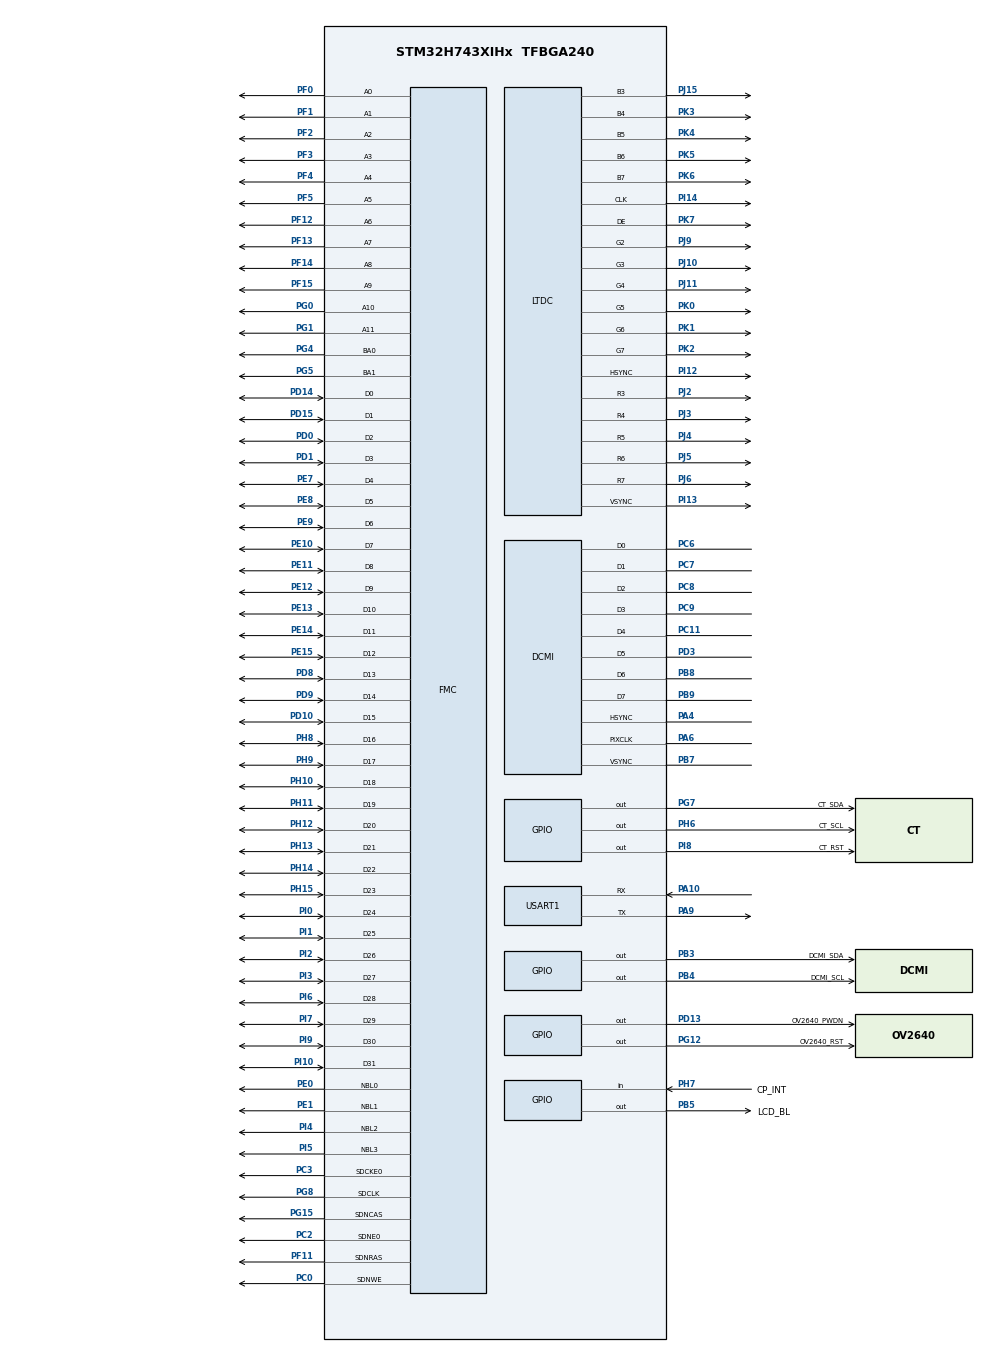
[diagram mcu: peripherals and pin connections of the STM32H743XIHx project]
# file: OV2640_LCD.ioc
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CORTEX_M7.AccessPermission_S-Cortex_Memory_Protection_Unit_Region1_Settings_S=MPU_REGION_FULL_ACCESS
CORTEX_M7.AccessPermission_S-Cortex_Memory_Protection_Unit_Region2_Settings_S=MPU_REGION_FULL_ACCESS
CORTEX_M7.AccessPermission_S-Cortex_Memory_Protection_Unit_Region3_Settings_S=MPU_REGION_FULL_ACCESS
CORTEX_M7.AccessPermission_S-Cortex_Memory_Protection_Unit_Region4_Settings_S=MPU_REGION_FULL_ACCESS
CORTEX_M7.AccessPermission_S-Cortex_Memory_Protection_Unit_Region5_Settings_S=MPU_REGION_FULL_ACCESS
CORTEX_M7.AccessPermission_Spec=MPU_REGION_FULL_ACCESS
CORTEX_M7.BaseAddress_S-Cortex_Memory_Protection_Unit_Region1_Settings_S=0x24000000
CORTEX_M7.BaseAddress_S-Cortex_Memory_Protection_Unit_Region2_Settings_S=0x30000000
CORTEX_M7.BaseAddress_S-Cortex_Memory_Protection_Unit_Region3_Settings_S=0x38000000
CORTEX_M7.BaseAddress_S-Cortex_Memory_Protection_Unit_Region4_Settings_S=0x80000000
CORTEX_M7.BaseAddress_S-Cortex_Memory_Protection_Unit_Region5_Settings_S=0xC0000000
CORTEX_M7.BaseAddress_Spec=0x20000000
CORTEX_M7.CPU_DCache=Enabled
CORTEX_M7.CPU_ICache=Enabled
CORTEX_M7.DisableExec_S-Cortex_Memory_Protection_Unit_Region4_Settings_S=MPU_INSTRUCTION_ACCESS_DISABLE
CORTEX_M7.DisableExec_Spec=MPU_INSTRUCTION_ACCESS_ENABLE
CORTEX_M7.Enable_S-Cortex_Memory_Protection_Unit_Region1_Settings_S=MPU_REGION_ENABLE
CORTEX_M7.Enable_S-Cortex_Memory_Protection_Unit_Region2_Settings_S=MPU_REGION_ENABLE
CORTEX_M7.Enable_S-Cortex_Memory_Protection_Unit_Region3_Settings_S=MPU_REGION_ENABLE
CORTEX_M7.Enable_S-Cortex_Memory_Protection_Unit_Region4_Settings_S=MPU_REGION_ENABLE
CORTEX_M7.Enable_S-Cortex_Memory_Protection_Unit_Region5_Settings_S=MPU_REGION_ENABLE
CORTEX_M7.IsBufferable_S-Cortex_Memory_Protection_Unit_Region1_Settings_S=MPU_ACCESS_BUFFERABLE
CORTEX_M7.IsBufferable_S-Cortex_Memory_Protection_Unit_Region2_Settings_S=MPU_ACCESS_BUFFERABLE
CORTEX_M7.IsBufferable_S-Cortex_Memory_Protection_Unit_Region3_Settings_S=MPU_ACCESS_BUFFERABLE
CORTEX_M7.IsBufferable_S-Cortex_Memory_Protection_Unit_Region5_Settings_S=MPU_ACCESS_BUFFERABLE
CORTEX_M7.IsBufferable_Spec=MPU_ACCESS_BUFFERABLE
CORTEX_M7.IsCacheable_S-Cortex_Memory_Protection_Unit_Region1_Settings_S=MPU_ACCESS_CACHEABLE
CORTEX_M7.IsCacheable_S-Cortex_Memory_Protection_Unit_Region2_Settings_S=MPU_ACCESS_CACHEABLE
CORTEX_M7.IsCacheable_S-Cortex_Memory_Protection_Unit_Region3_Settings_S=MPU_ACCESS_CACHEABLE
CORTEX_M7.IsCacheable_S-Cortex_Memory_Protection_Unit_Region5_Settings_S=MPU_ACCESS_CACHEABLE
CORTEX_M7.IsCacheable_Spec=MPU_ACCESS_CACHEABLE
CORTEX_M7.IsShareable_Spec=MPU_ACCESS_NOT_SHAREABLE
CORTEX_M7.Size_S-Cortex_Memory_Protection_Unit_Region1_Settings_S=MPU_REGION_SIZE_512KB
CORTEX_M7.Size_S-Cortex_Memory_Protection_Unit_Region2_Settings_S=MPU_REGION_SIZE_512KB
CORTEX_M7.Size_S-Cortex_Memory_Protection_Unit_Region3_Settings_S=MPU_REGION_SIZE_64KB
CORTEX_M7.Size_S-Cortex_Memory_Protection_Unit_Region4_Settings_S=MPU_REGION_SIZE_256MB
CORTEX_M7.Size_S-Cortex_Memory_Protection_Unit_Region5_Settings_S=MPU_REGION_SIZE_64MB
CORTEX_M7.Size_Spec=MPU_REGION_SIZE_128KB
CORTEX_M7.SubRegionDisable_Spec=0x00
CORTEX_M7.default_mode_Activation=1
DCMI.PCKPolarity=DCMI_PCKPOLARITY_RISING
DMA2D.ColorMode=DMA2D_OUTPUT_RGB565
Dma.DCMI.1.Direction=DMA_PERIPH_TO_MEMORY
Dma.DCMI.1.EventEnable=DISABLE
Dma.DCMI.1.FIFOMode=DMA_FIFOMODE_ENABLE
Dma.DCMI.1.FIFOThreshold=DMA_FIFO_THRESHOLD_HALFFULL
Dma.DCMI.1.Instance=DMA1_Stream1
Dma.DCMI.1.MemBurst=DMA_MBURST_SINGLE
Dma.DCMI.1.MemDataAlignment=DMA_MDATAALIGN_WORD
Dma.DCMI.1.MemInc=DMA_MINC_ENABLE
Dma.DCMI.1.Mode=DMA_CIRCULAR
Dma.DCMI.1.PeriphBurst=DMA_PBURST_SINGLE
Dma.DCMI.1.PeriphDataAlignment=DMA_PDATAALIGN_WORD
Dma.DCMI.1.PeriphInc=DMA_PINC_DISABLE
Dma.DCMI.1.Polarity=HAL_DMAMUX_REQ_GEN_RISING
Dma.DCMI.1.Priority=DMA_PRIORITY_HIGH
Dma.DCMI.1.RequestNumber=1
Dma.DCMI.1.SignalID=NONE
Dma.DCMI.1.SyncEnable=DISABLE
Dma.DCMI.1.SyncPolarity=HAL_DMAMUX_SYNC_NO_EVENT
Dma.DCMI.1.SyncRequestNumber=1
Dma.DCMI.1.SyncSignalID=NONE
Dma.Request0=USART1_RX
Dma.Request1=DCMI
Dma.USART1_RX.0.Direction=DMA_PERIPH_TO_MEMORY
Dma.USART1_RX.0.EventEnable=DISABLE
Dma.USART1_RX.0.FIFOMode=DMA_FIFOMODE_DISABLE
Dma.USART1_RX.0.Instance=DMA1_Stream0
Dma.USART1_RX.0.MemDataAlignment=DMA_MDATAALIGN_BYTE
Dma.USART1_RX.0.MemInc=DMA_MINC_ENABLE
Dma.USART1_RX.0.Mode=DMA_NORMAL
Dma.USART1_RX.0.PeriphDataAlignment=DMA_PDATAALIGN_BYTE
Dma.USART1_RX.0.PeriphInc=DMA_PINC_DISABLE
Dma.USART1_RX.0.Polarity=HAL_DMAMUX_REQ_GEN_RISING
Dma.USART1_RX.0.Priority=DMA_PRIORITY_LOW
Dma.USART1_RX.0.RequestNumber=1
Dma.USART1_RX.0.SignalID=NONE
Dma.USART1_RX.0.SyncEnable=DISABLE
Dma.USART1_RX.0.SyncPolarity=HAL_DMAMUX_SYNC_NO_EVENT
Dma.USART1_RX.0.SyncRequestNumber=1
Dma.USART1_RX.0.SyncSignalID=NONE
FMC.CASLatency1=FMC_SDRAM_CAS_LATENCY_2
FMC.ColumnBitsNumber1=FMC_SDRAM_COLUMN_BITS_NUM_9
FMC.ExitSelfRefreshDelay1=8
FMC.LoadToActiveDelay1=2
FMC.RCDDelay1=2
FMC.RPDelay1=2
FMC.RPDelay2=2
FMC.ReadBurst1=FMC_SDRAM_RBURST_ENABLE
FMC.ReadBurst2=FMC_SDRAM_RBURST_ENABLE
FMC.RowCycleDelay1=8
FMC.RowCycleDelay2=8
FMC.SDClockPeriod1=FMC_SDRAM_CLOCK_PERIOD_2
FMC.SDClockPeriod2=FMC_SDRAM_CLOCK_PERIOD_2
FMC.SelfRefreshTime1=5
FMC.WriteRecoveryTime1=4
LTDC.ActiveH=272
LTDC.ActiveW=480
LTDC.Alpha_L0=255
LTDC.BlendingFactor1_L0=LTDC_BLENDING_FACTOR1_PAxCA
LTDC.BlendingFactor2_L0=LTDC_BLENDING_FACTOR2_PAxCA
LTDC.FBStartAdress_L0=0xC0000000
LTDC.HBP=40
LTDC.HFP=5
LTDC.HSync=1
LTDC.ImageWidth_L0=480
LTDC.Layers=0
LTDC.PixelFormat_L0=LTDC_PIXEL_FORMAT_RGB565
LTDC.VBP=8
LTDC.VFP=3
LTDC.VSync=1
LTDC.WindowX1_L0=480
LTDC.WindowY1_L0=272
Mcu.Family=STM32H7
Mcu.Name=STM32H743XIHx
Mcu.Package=TFBGA240
NVIC.DCMI_IRQn=true\:0\:0\:false\:false\:true\:true\:true\:true
NVIC.DMA1_Stream0_IRQn=true\:0\:0\:false\:false\:true\:false\:true\:true
NVIC.DMA1_Stream1_IRQn=true\:0\:0\:false\:false\:true\:false\:true\:true
NVIC.PriorityGroup=NVIC_PRIORITYGROUP_4
NVIC.USART1_IRQn=true\:0\:0\:false\:false\:true\:true\:true\:true
PA10.Mode=Asynchronous
PA10.Signal=USART1_RX
PA13\ (JTMS/SWDIO).Mode=Serial_Wire
PA13\ (JTMS/SWDIO).Signal=DEBUG_JTMS-SWDIO
PA14\ (JTCK/SWCLK).Mode=Serial_Wire
PA14\ (JTCK/SWCLK).Signal=DEBUG_JTCK-SWCLK
PA4.GPIO_Speed=GPIO_SPEED_FREQ_VERY_HIGH
PA4.Mode=Slave_8_bits_External_Synchro
PA4.Signal=DCMI_HSYNC
PA6.GPIO_Speed=GPIO_SPEED_FREQ_VERY_HIGH
PA6.Mode=Slave_8_bits_External_Synchro
PA6.Signal=DCMI_PIXCLK
PA9.Mode=Asynchronous
PA9.Signal=USART1_TX
PB3\ (JTDO/TRACESWO).GPIO_Label=DCMI_SDA
PB3\ (JTDO/TRACESWO).GPIO_ModeDefaultOutputPP=GPIO_MODE_OUTPUT_OD
PB3\ (JTDO/TRACESWO).GPIO_PuPd=GPIO_PULLUP
PB3\ (JTDO/TRACESWO).GPIO_Speed=GPIO_SPEED_FREQ_VERY_HIGH
PB3\ (JTDO/TRACESWO).PinState=GPIO_PIN_SET
PB3\ (JTDO/TRACESWO).Signal=GPIO_Output
PB4\ (NJTRST).GPIO_Label=DCMI_SCL
PB4\ (NJTRST).GPIO_PuPd=GPIO_PULLUP
PB4\ (NJTRST).GPIO_Speed=GPIO_SPEED_FREQ_VERY_HIGH
PB4\ (NJTRST).PinState=GPIO_PIN_SET
PB4\ (NJTRST).Signal=GPIO_Output
PB5.GPIO_Label=LCD_BL
PB5.GPIO_PuPd=GPIO_PULLDOWN
PB5.GPIO_Speed=GPIO_SPEED_FREQ_HIGH
PB5.Signal=GPIO_Output
PB7.GPIO_Speed=GPIO_SPEED_FREQ_VERY_HIGH
PB7.Mode=Slave_8_bits_External_Synchro
PB7.Signal=DCMI_VSYNC
PB8.GPIO_Speed=GPIO_SPEED_FREQ_VERY_HIGH
PB8.Mode=Slave_8_bits_External_Synchro
PB8.Signal=DCMI_D6
PB9.GPIO_Speed=GPIO_SPEED_FREQ_VERY_HIGH
PB9.Mode=Slave_8_bits_External_Synchro
PB9.Signal=DCMI_D7
PC0.Signal=FMC_SDNWE
PC11.GPIO_Speed=GPIO_SPEED_FREQ_VERY_HIGH
PC11.Mode=Slave_8_bits_External_Synchro
PC11.Signal=DCMI_D4
PC14-OSC32_IN\ (OSC32_IN).Mode=LSE-External-Oscillator
PC14-OSC32_IN\ (OSC32_IN).Signal=RCC_OSC32_IN
PC15-OSC32_OUT\ (OSC32_OUT).Mode=LSE-External-Oscillator
PC15-OSC32_OUT\ (OSC32_OUT).Signal=RCC_OSC32_OUT
PC2.Mode=SdramChipSelect1_1
PC2.Signal=FMC_SDNE0
PC3.Mode=SdramChipSelect1_1
PC3.Signal=FMC_SDCKE0
PC6.GPIO_Speed=GPIO_SPEED_FREQ_VERY_HIGH
PC6.Mode=Slave_8_bits_External_Synchro
PC6.Signal=DCMI_D0
PC7.GPIO_Speed=GPIO_SPEED_FREQ_VERY_HIGH
PC7.Mode=Slave_8_bits_External_Synchro
PC7.Signal=DCMI_D1
PC8.GPIO_Speed=GPIO_SPEED_FREQ_VERY_HIGH
PC8.Mode=Slave_8_bits_External_Synchro
PC8.Signal=DCMI_D2
PC9.GPIO_Speed=GPIO_SPEED_FREQ_VERY_HIGH
PC9.Mode=Slave_8_bits_External_Synchro
PC9.Signal=DCMI_D3
PD0.Signal=FMC_D2_DA2
PD1.Signal=FMC_D3_DA3
PD10.Signal=FMC_D15_DA15
PD13.GPIO_Label=OV2640_PWDN
PD13.GPIO_PuPd=GPIO_PULLUP
PD13.GPIO_Speed=GPIO_SPEED_FREQ_HIGH
PD13.Signal=GPIO_Output
PD14.Signal=FMC_D0_DA0
PD15.Signal=FMC_D1_DA1
PD3.GPIO_Speed=GPIO_SPEED_FREQ_VERY_HIGH
PD3.Mode=Slave_8_bits_External_Synchro
PD3.Signal=DCMI_D5
PD8.Signal=FMC_D13_DA13
PD9.Signal=FMC_D14_DA14
PE0.Signal=FMC_NBL0
PE1.Signal=FMC_NBL1
PE10.Signal=FMC_D7_DA7
PE11.Signal=FMC_D8_DA8
PE12.Signal=FMC_D9_DA9
PE13.Signal=FMC_D10_DA10
PE14.Signal=FMC_D11_DA11
PE15.Signal=FMC_D12_DA12
PE7.Signal=FMC_D4_DA4
PE8.Signal=FMC_D5_DA5
PE9.Signal=FMC_D6_DA6
PF0.Signal=FMC_A0
PF1.Signal=FMC_A1
PF11.Signal=FMC_SDNRAS
PF12.Signal=FMC_A6
PF13.Signal=FMC_A7
PF14.Signal=FMC_A8
PF15.Signal=FMC_A9
PF2.Signal=FMC_A2
PF3.Signal=FMC_A3
PF4.Signal=FMC_A4
PF5.Signal=FMC_A5
PG0.Signal=FMC_A10
PG1.Signal=FMC_A11
PG12.GPIO_Label=OV2640_RST
PG12.GPIO_PuPd=GPIO_PULLUP
PG12.GPIO_Speed=GPIO_SPEED_FREQ_HIGH
PG12.Signal=GPIO_Output
PG15.Signal=FMC_SDNCAS
PG4.Signal=FMC_A14_BA0
PG5.Signal=FMC_A15_BA1
PG7.GPIO_Label=CT_SDA
PG7.GPIO_ModeDefaultOutputPP=GPIO_MODE_OUTPUT_OD
PG7.GPIO_PuPd=GPIO_PULLUP
PG7.GPIO_Speed=GPIO_SPEED_FREQ_VERY_HIGH
PG7.PinState=GPIO_PIN_SET
PG7.Signal=GPIO_Output
PG8.Signal=FMC_SDCLK
PH0-OSC_IN\ (PH0).Mode=HSE-External-Oscillator
PH0-OSC_IN\ (PH0).Signal=RCC_OSC_IN
PH1-OSC_OUT\ (PH1).Mode=HSE-External-Oscillator
PH1-OSC_OUT\ (PH1).Signal=RCC_OSC_OUT
PH10.Signal=FMC_D18
PH11.Signal=FMC_D19
PH12.Signal=FMC_D20
PH13.Signal=FMC_D21
PH14.Signal=FMC_D22
PH15.Signal=FMC_D23
PH6.GPIO_Label=CT_SCL
PH6.GPIO_ModeDefaultOutputPP=GPIO_MODE_OUTPUT_PP
PH6.GPIO_PuPd=GPIO_NOPULL
PH6.GPIO_Speed=GPIO_SPEED_FREQ_VERY_HIGH
PH6.PinState=GPIO_PIN_SET
PH6.Signal=GPIO_Output
PH7.GPIO_Label=CP_INT
PH7.GPIO_PuPd=GPIO_NOPULL
PH7.Signal=GPIO_Input
PH8.Signal=FMC_D16
PH9.Signal=FMC_D17
PI0.Signal=FMC_D24
PI1.Signal=FMC_D25
PI10.Signal=FMC_D31
PI12.GPIO_Speed=GPIO_SPEED_FREQ_VERY_HIGH
PI12.Mode=RGB565
PI12.Signal=LTDC_HSYNC
PI13.GPIO_Speed=GPIO_SPEED_FREQ_VERY_HIGH
PI13.Mode=RGB565
PI13.Signal=LTDC_VSYNC
PI14.GPIO_Speed=GPIO_SPEED_FREQ_VERY_HIGH
PI14.Mode=RGB565
PI14.Signal=LTDC_CLK
PI2.Signal=FMC_D26
PI3.Signal=FMC_D27
PI4.Signal=FMC_NBL2
PI5.Signal=FMC_NBL3
PI6.Signal=FMC_D28
PI7.Signal=FMC_D29
PI8.GPIO_Label=CT_RST
PI8.GPIO_PuPd=GPIO_PULLUP
PI8.PinState=GPIO_PIN_SET
PI8.Signal=GPIO_Output
PI9.Signal=FMC_D30
PJ10.GPIO_Speed=GPIO_SPEED_FREQ_VERY_HIGH
PJ10.Mode=RGB565
PJ10.Signal=LTDC_G3
PJ11.GPIO_Speed=GPIO_SPEED_FREQ_VERY_HIGH
PJ11.Mode=RGB565
PJ11.Signal=LTDC_G4
PJ15.GPIO_Speed=GPIO_SPEED_FREQ_VERY_HIGH
PJ15.Mode=RGB565
PJ15.Signal=LTDC_B3
PJ2.GPIO_Speed=GPIO_SPEED_FREQ_VERY_HIGH
PJ2.Mode=RGB565
PJ2.Signal=LTDC_R3
PJ3.GPIO_Speed=GPIO_SPEED_FREQ_VERY_HIGH
PJ3.Mode=RGB565
PJ3.Signal=LTDC_R4
PJ4.GPIO_Speed=GPIO_SPEED_FREQ_VERY_HIGH
PJ4.Mode=RGB565
PJ4.Signal=LTDC_R5
PJ5.GPIO_Speed=GPIO_SPEED_FREQ_VERY_HIGH
PJ5.Mode=RGB565
PJ5.Signal=LTDC_R6
PJ6.GPIO_Speed=GPIO_SPEED_FREQ_VERY_HIGH
PJ6.Mode=RGB565
PJ6.Signal=LTDC_R7
PJ9.GPIO_Speed=GPIO_SPEED_FREQ_VERY_HIGH
PJ9.Mode=RGB565
PJ9.Signal=LTDC_G2
PK0.GPIO_Speed=GPIO_SPEED_FREQ_VERY_HIGH
PK0.Mode=RGB565
PK0.Signal=LTDC_G5
PK1.GPIO_Speed=GPIO_SPEED_FREQ_VERY_HIGH
PK1.Mode=RGB565
PK1.Signal=LTDC_G6
PK2.GPIO_Speed=GPIO_SPEED_FREQ_VERY_HIGH
PK2.Mode=RGB565
PK2.Signal=LTDC_G7
PK3.GPIO_Speed=GPIO_SPEED_FREQ_VERY_HIGH
PK3.Mode=RGB565
PK3.Signal=LTDC_B4
PK4.GPIO_Speed=GPIO_SPEED_FREQ_VERY_HIGH
PK4.Mode=RGB565
PK4.Signal=LTDC_B5
PK5.GPIO_Speed=GPIO_SPEED_FREQ_VERY_HIGH
PK5.Mode=RGB565
PK5.Signal=LTDC_B6
PK6.GPIO_Speed=GPIO_SPEED_FREQ_VERY_HIGH
PK6.Mode=RGB565
PK6.Signal=LTDC_B7
PK7.GPIO_Speed=GPIO_SPEED_FREQ_VERY_HIGH
PK7.Mode=RGB565
PK7.Signal=LTDC_DE
ProjectManager.HeapSize=0x200
ProjectManager.StackSize=0x400
ProjectManager.TargetToolchain=MDK-ARM V5.32
RCC.ADCFreq_Value=50390625
RCC.APB1Freq_Value=120000000
RCC.APB2Freq_Value=120000000
RCC.APB3Freq_Value=120000000
RCC.APB4Freq_Value=120000000
RCC.CortexFreq_Value=480000000
RCC.D1PPRE=RCC_APB3_DIV2
RCC.D2PPRE1=RCC_APB1_DIV2
RCC.D2PPRE2=RCC_APB2_DIV2
RCC.D3PPRE=RCC_APB4_DIV2
RCC.DIVM1=5
RCC.DIVM3=25
RCC.DIVN1=192
RCC.DIVN3=180
RCC.DIVR3=20
RCC.HCLKFreq_Value=240000000
RCC.HPRE=RCC_HCLK_DIV2
RCC.PLLFRACN=0
RCC.PLLSourceVirtual=RCC_PLLSOURCE_HSE
RCC.SYSCLKFreq_VALUE=480000000
RCC.SYSCLKSource=RCC_SYSCLKSOURCE_PLLCLK
RCC.USBFreq_Value=480000000
SH.FMC_A0.0=FMC_A0,12b-sda1
SH.FMC_A1.0=FMC_A1,12b-sda1
SH.FMC_A10.0=FMC_A10,12b-sda1
SH.FMC_A11.0=FMC_A11,12b-sda1
SH.FMC_A14_BA0.0=FMC_BA0,FourSdramBanks1
SH.FMC_A15_BA1.0=FMC_BA1,FourSdramBanks1
SH.FMC_A2.0=FMC_A2,12b-sda1
SH.FMC_A3.0=FMC_A3,12b-sda1
SH.FMC_A4.0=FMC_A4,12b-sda1
SH.FMC_A5.0=FMC_A5,12b-sda1
SH.FMC_A6.0=FMC_A6,12b-sda1
SH.FMC_A7.0=FMC_A7,12b-sda1
SH.FMC_A8.0=FMC_A8,12b-sda1
SH.FMC_A9.0=FMC_A9,12b-sda1
SH.FMC_D0_DA0.0=FMC_D0,sd-32b-d1
SH.FMC_D10_DA10.0=FMC_D10,sd-32b-d1
SH.FMC_D11_DA11.0=FMC_D11,sd-32b-d1
SH.FMC_D12_DA12.0=FMC_D12,sd-32b-d1
SH.FMC_D13_DA13.0=FMC_D13,sd-32b-d1
SH.FMC_D14_DA14.0=FMC_D14,sd-32b-d1
SH.FMC_D15_DA15.0=FMC_D15,sd-32b-d1
SH.FMC_D16.0=FMC_D16,sd-32b-d1
SH.FMC_D17.0=FMC_D17,sd-32b-d1
SH.FMC_D18.0=FMC_D18,sd-32b-d1
SH.FMC_D19.0=FMC_D19,sd-32b-d1
SH.FMC_D1_DA1.0=FMC_D1,sd-32b-d1
SH.FMC_D20.0=FMC_D20,sd-32b-d1
SH.FMC_D21.0=FMC_D21,sd-32b-d1
SH.FMC_D22.0=FMC_D22,sd-32b-d1
SH.FMC_D23.0=FMC_D23,sd-32b-d1
SH.FMC_D24.0=FMC_D24,sd-32b-d1
SH.FMC_D25.0=FMC_D25,sd-32b-d1
SH.FMC_D26.0=FMC_D26,sd-32b-d1
SH.FMC_D27.0=FMC_D27,sd-32b-d1
SH.FMC_D28.0=FMC_D28,sd-32b-d1
SH.FMC_D29.0=FMC_D29,sd-32b-d1
SH.FMC_D2_DA2.0=FMC_D2,sd-32b-d1
SH.FMC_D30.0=FMC_D30,sd-32b-d1
SH.FMC_D31.0=FMC_D31,sd-32b-d1
SH.FMC_D3_DA3.0=FMC_D3,sd-32b-d1
SH.FMC_D4_DA4.0=FMC_D4,sd-32b-d1
SH.FMC_D5_DA5.0=FMC_D5,sd-32b-d1
SH.FMC_D6_DA6.0=FMC_D6,sd-32b-d1
SH.FMC_D7_DA7.0=FMC_D7,sd-32b-d1
SH.FMC_D8_DA8.0=FMC_D8,sd-32b-d1
SH.FMC_D9_DA9.0=FMC_D9,sd-32b-d1
SH.FMC_NBL0.0=FMC_NBL0,Sd4ByteEnable1
SH.FMC_NBL1.0=FMC_NBL1,Sd4ByteEnable1
SH.FMC_NBL2.0=FMC_NBL2,Sd4ByteEnable1
SH.FMC_NBL3.0=FMC_NBL3,Sd4ByteEnable1
SH.FMC_SDCLK.0=FMC_SDCLK,12b-sda1
SH.FMC_SDNCAS.0=FMC_SDNCAS,12b-sda1
SH.FMC_SDNRAS.0=FMC_SDNRAS,12b-sda1
SH.FMC_SDNWE.0=FMC_SDNWE,12b-sda1
TIM14.Prescaler=240-1
USART1.VirtualMode-Asynchronous=VM_ASYNC
VP_DMA2D_VS_DMA2D.Mode=DMA2D_Activate
VP_MEMORYMAP_VS_MEMORYMAP.Mode=CurAppReg
VP_TIM14_VS_ClockSourceINT.Mode=Enable_Timer
board=custom

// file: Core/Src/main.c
/* USER CODE BEGIN Header */
/**
  ******************************************************************************
  * @file           : main.c
  * @brief          : Main program body
  ******************************************************************************
  * @attention
  *
  * Copyright (c) 2026 STMicroelectronics.
  * All rights reserved.
  *
  * This software is licensed under terms that can be found in the LICENSE file
  * in the root directory of this software component.
  * If no LICENSE file comes with this software, it is provided AS-IS.
  *
  ******************************************************************************
  */
/* USER CODE END Header */
#include "main.h"
#include "dcmi.h"
#include "dma.h"
#include "dma2d.h"
#include "ltdc.h"
#include "tim.h"
#include "usart.h"
#include "gpio.h"
#include "fmc.h"

/* USER CODE BEGIN Includes */
#include "bsp_system.h"
/* USER CODE END Includes */

void SystemClock_Config(void);
static void MPU_Config(void);

int main(void)
{

  /* MPU Configuration--------------------------------------------------------*/
  MPU_Config();

  /* Enable the CPU Cache */

  /* Enable I-Cache---------------------------------------------------------*/
  SCB_EnableICache();

  /* Enable D-Cache---------------------------------------------------------*/
  SCB_EnableDCache();

  /* MCU Configuration--------------------------------------------------------*/

  /* Reset of all peripherals, Initializes the Flash interface and the Systick. */
  HAL_Init();

  /* Configure the system clock */
  SystemClock_Config();

  /* Initialize all configured peripherals */
  MX_GPIO_Init();
  MX_DMA_Init();
  MX_USART1_UART_Init();
  MX_DMA2D_Init();
  MX_LTDC_Init();
  MX_FMC_Init();
  MX_DCMI_Init();
  MX_TIM14_Init();
  /* USER CODE BEGIN 2 */
	Uart_Init();
	SDRAM_Init();
	LCD_Init();
	LCD_Clear(BLACK);
//	GT9XX_Init();
	sccb_init();
	ov2640_init();
	ov2640_rgb565_mode();
	OV2640_ImageWin_Set(0, 0, 1600, 1200);
	OV2640_OutSize_Set(480, 272);
	OV2640_Light_Mode(0);
	OV2640_Brightness(4);
	OV2640_Special_Effects(0);

	DCMI_Init();
	DCMI_DMA_Init(
			LCD_FRAME_BUF_ADDR,
			0,
			480 * 272 /2,
			DMA_MDATAALIGN_WORD,
			DMA_MINC_ENABLE
	);

	dcmi_start();
//	HAL_DCMI_Start_DMA(&hdcmi, DCMI_MODE_CONTINUOUS,LCD_FRAME_BUF_ADDR,480*272);
//	LCD_Show_String(1,1,480,16,16,"lcd_touch_test",RED);
  /* USER CODE END 2 */

  /* Infinite loop */
  /* USER CODE BEGIN WHILE */
  while (1)
  {

//		GT9XX_Scan();
		uart_proc();
    /* USER CODE END WHILE */

  }
}

void SystemClock_Config(void)
{
  RCC_OscInitTypeDef RCC_OscInitStruct = {0};
  RCC_ClkInitTypeDef RCC_ClkInitStruct = {0};

  /** Supply configuration update enable
  */
  HAL_PWREx_ConfigSupply(PWR_LDO_SUPPLY);

  /** Configure the main internal regulator output voltage
  */
  __HAL_PWR_VOLTAGESCALING_CONFIG(PWR_REGULATOR_VOLTAGE_SCALE0);

  while(!__HAL_PWR_GET_FLAG(PWR_FLAG_VOSRDY)) {}

  /** Initializes the RCC Oscillators according to the specified parameters
  * in the RCC_OscInitTypeDef structure.
  */
  RCC_OscInitStruct.OscillatorType = RCC_OSCILLATORTYPE_HSE;
  RCC_OscInitStruct.HSEState = RCC_HSE_ON;
  RCC_OscInitStruct.PLL.PLLState = RCC_PLL_ON;
  RCC_OscInitStruct.PLL.PLLSource = RCC_PLLSOURCE_HSE;
  RCC_OscInitStruct.PLL.PLLM = 5;
  RCC_OscInitStruct.PLL.PLLN = 192;
  RCC_OscInitStruct.PLL.PLLP = 2;
  RCC_OscInitStruct.PLL.PLLQ = 2;
  RCC_OscInitStruct.PLL.PLLR = 2;
  RCC_OscInitStruct.PLL.PLLRGE = RCC_PLL1VCIRANGE_2;
  RCC_OscInitStruct.PLL.PLLVCOSEL = RCC_PLL1VCOWIDE;
  RCC_OscInitStruct.PLL.PLLFRACN = 0;
  if (HAL_RCC_OscConfig(&RCC_OscInitStruct) != HAL_OK)
  {
    Error_Handler();
  }

  /** Initializes the CPU, AHB and APB buses clocks
  */
  RCC_ClkInitStruct.ClockType = RCC_CLOCKTYPE_HCLK|RCC_CLOCKTYPE_SYSCLK
                              |RCC_CLOCKTYPE_PCLK1|RCC_CLOCKTYPE_PCLK2
                              |RCC_CLOCKTYPE_D3PCLK1|RCC_CLOCKTYPE_D1PCLK1;
  RCC_ClkInitStruct.SYSCLKSource = RCC_SYSCLKSOURCE_PLLCLK;
  RCC_ClkInitStruct.SYSCLKDivider = RCC_SYSCLK_DIV1;
  RCC_ClkInitStruct.AHBCLKDivider = RCC_HCLK_DIV2;
  RCC_ClkInitStruct.APB3CLKDivider = RCC_APB3_DIV2;
  RCC_ClkInitStruct.APB1CLKDivider = RCC_APB1_DIV2;
  RCC_ClkInitStruct.APB2CLKDivider = RCC_APB2_DIV2;
  RCC_ClkInitStruct.APB4CLKDivider = RCC_APB4_DIV2;

  if (HAL_RCC_ClockConfig(&RCC_ClkInitStruct, FLASH_LATENCY_4) != HAL_OK)
  {
    Error_Handler();
  }
}

 /* MPU Configuration */

void MPU_Config(void)
{
  MPU_Region_InitTypeDef MPU_InitStruct = {0};

  /* Disables the MPU */
  HAL_MPU_Disable();

  /** Initializes and configures the Region and the memory to be protected
  */
  MPU_InitStruct.Enable = MPU_REGION_ENABLE;
  MPU_InitStruct.Number = MPU_REGION_NUMBER0;
  MPU_InitStruct.BaseAddress = 0x20000000;
  MPU_InitStruct.Size = MPU_REGION_SIZE_128KB;
  MPU_InitStruct.SubRegionDisable = 0x00;
  MPU_InitStruct.TypeExtField = MPU_TEX_LEVEL0;
  MPU_InitStruct.AccessPermission = MPU_REGION_FULL_ACCESS;
  MPU_InitStruct.DisableExec = MPU_INSTRUCTION_ACCESS_ENABLE;
  MPU_InitStruct.IsShareable = MPU_ACCESS_NOT_SHAREABLE;
  MPU_InitStruct.IsCacheable = MPU_ACCESS_CACHEABLE;
  MPU_InitStruct.IsBufferable = MPU_ACCESS_BUFFERABLE;

  HAL_MPU_ConfigRegion(&MPU_InitStruct);

  /** Initializes and configures the Region and the memory to be protected
  */
  MPU_InitStruct.Number = MPU_REGION_NUMBER1;
  MPU_InitStruct.BaseAddress = 0x24000000;
  MPU_InitStruct.Size = MPU_REGION_SIZE_512KB;
  MPU_InitStruct.SubRegionDisable = 0x0;

  HAL_MPU_ConfigRegion(&MPU_InitStruct);

  /** Initializes and configures the Region and the memory to be protected
  */
  MPU_InitStruct.Number = MPU_REGION_NUMBER2;
  MPU_InitStruct.BaseAddress = 0x30000000;

  HAL_MPU_ConfigRegion(&MPU_InitStruct);

  /** Initializes and configures the Region and the memory to be protected
  */
  MPU_InitStruct.Number = MPU_REGION_NUMBER3;
  MPU_InitStruct.BaseAddress = 0x38000000;
  MPU_InitStruct.Size = MPU_REGION_SIZE_64KB;

  HAL_MPU_ConfigRegion(&MPU_InitStruct);

  /** Initializes and configures the Region and the memory to be protected
  */
  MPU_InitStruct.Number = MPU_REGION_NUMBER4;
  MPU_InitStruct.BaseAddress = 0x80000000;
  MPU_InitStruct.Size = MPU_REGION_SIZE_256MB;
  MPU_InitStruct.DisableExec = MPU_INSTRUCTION_ACCESS_DISABLE;
  MPU_InitStruct.IsCacheable = MPU_ACCESS_NOT_CACHEABLE;
  MPU_InitStruct.IsBufferable = MPU_ACCESS_NOT_BUFFERABLE;

  HAL_MPU_ConfigRegion(&MPU_InitStruct);

  /** Initializes and configures the Region and the memory to be protected
  */
  MPU_InitStruct.Number = MPU_REGION_NUMBER5;
  MPU_InitStruct.BaseAddress = 0xC0000000;
  MPU_InitStruct.Size = MPU_REGION_SIZE_64MB;
  MPU_InitStruct.DisableExec = MPU_INSTRUCTION_ACCESS_ENABLE;
  MPU_InitStruct.IsCacheable = MPU_ACCESS_CACHEABLE;
  MPU_InitStruct.IsBufferable = MPU_ACCESS_BUFFERABLE;

  HAL_MPU_ConfigRegion(&MPU_InitStruct);
  /* Enables the MPU */
  HAL_MPU_Enable(MPU_PRIVILEGED_DEFAULT);

}

void Error_Handler(void)
{
  __disable_irq();
  while (1)
  {
  }
}
